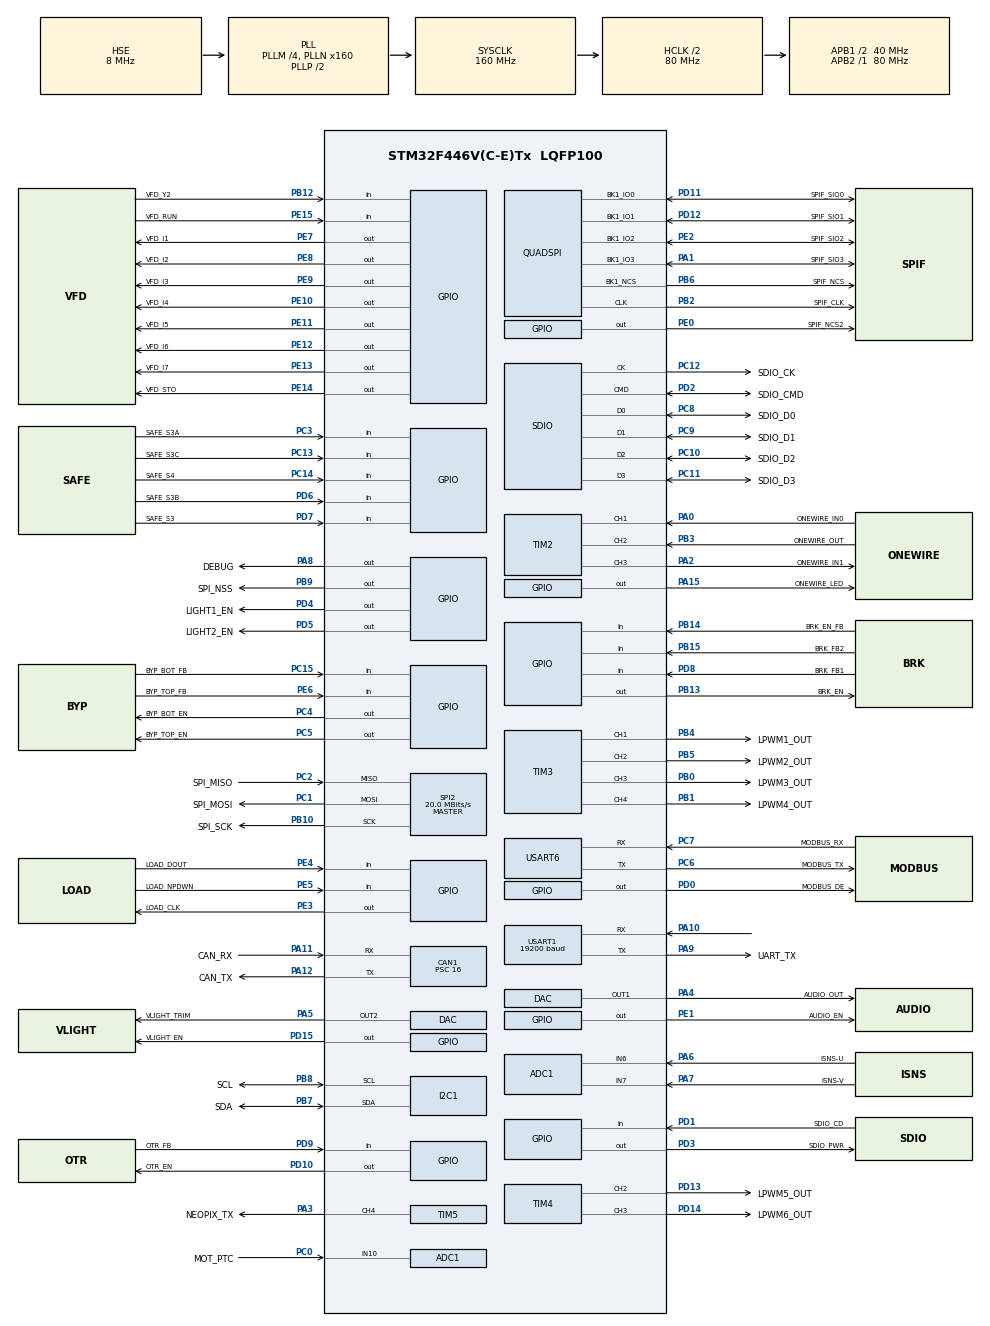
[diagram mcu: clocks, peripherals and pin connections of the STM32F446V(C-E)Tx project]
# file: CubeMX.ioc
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ADC1.Channel-1\#ChannelRegularConversion=ADC_CHANNEL_6
ADC1.NbrOfConversionFlag=1
ADC1.Rank-1\#ChannelRegularConversion=1
ADC1.SamplingTime-1\#ChannelRegularConversion=ADC_SAMPLETIME_3CYCLES
ADC1.master=1
CAN1.ABOM=ENABLE
CAN1.BS1=CAN_BS1_16TQ
CAN1.BS2=CAN_BS2_3TQ
CAN1.CalculateBaudRate=125000
CAN1.CalculateTimeBit=8000
CAN1.CalculateTimeQuantum=400.0
CAN1.NART=ENABLE
CAN1.Prescaler=16
DAC.DAC_Trigger=DAC_TRIGGER_T6_TRGO
DAC.DAC_Trigger2=DAC_TRIGGER_SOFTWARE
Mcu.Family=STM32F4
Mcu.Name=STM32F446V(C-E)Tx
Mcu.Package=LQFP100
NVIC.PriorityGroup=NVIC_PRIORITYGROUP_4
NVIC.USART1_IRQn=true\:0\:0\:false\:false\:true\:true\:true\:true
PA0-WKUP.GPIO_Label=ONEWIRE_IN0
PA0-WKUP.Signal=S_TIM2_CH1_ETR
PA1.GPIO_Label=SPIF_SIO3
PA1.Mode=Single Bank 1
PA1.Signal=QUADSPI_BK1_IO3
PA10.Mode=Asynchronous
PA10.Signal=USART1_RX
PA11.GPIO_Label=CAN_RX
PA11.Mode=CAN_Activate
PA11.Signal=CAN1_RX
PA12.GPIO_Label=CAN_TX
PA12.Mode=CAN_Activate
PA12.Signal=CAN1_TX
PA13.GPIO_Label=SWDIO
PA13.Mode=Serial_Wire
PA13.Signal=SYS_JTMS-SWDIO
PA14.GPIO_Label=SWCLK
PA14.Mode=Serial_Wire
PA14.Signal=SYS_JTCK-SWCLK
PA15.GPIO_Label=ONEWIRE_LED
PA15.Signal=GPIO_Output
PA2.GPIO_Label=ONEWIRE_IN1
PA2.Signal=S_TIM2_CH3
PA3.GPIO_Label=NEOPIX_TX
PA3.Signal=S_TIM5_CH4
PA4.GPIO_Label=AUDIO_OUT
PA4.Signal=COMP_DAC1_group
PA5.GPIO_Label=VLIGHT_TRIM
PA5.Signal=COMP_DAC2_group
PA6.GPIO_Label=ISNS-U
PA6.Signal=ADCx_IN6
PA7.GPIO_Label=ISNS-V
PA7.Signal=ADCx_IN7
PA8.GPIO_Label=DEBUG
PA8.Signal=GPIO_Output
PA9.GPIO_Label=UART_TX
PA9.Mode=Asynchronous
PA9.Signal=USART1_TX
PB0.GPIO_Label=LPWM3_OUT
PB0.Signal=S_TIM3_CH3
PB1.GPIO_Label=LPWM4_OUT
PB1.Signal=S_TIM3_CH4
PB10.GPIO_Label=SPI_SCK
PB10.Mode=Full_Duplex_Master
PB10.Signal=SPI2_SCK
PB12.GPIO_Label=VFD_Y2
PB12.Signal=GPIO_Input
PB13.GPIO_Label=BRK_EN
PB13.Signal=GPIO_Output
PB14.GPIO_Label=BRK_EN_FB
PB14.Signal=GPIO_Input
PB15.GPIO_Label=BRK_FB2
PB15.Signal=GPIO_Input
PB2.GPIO_Label=SPIF_CLK
PB2.Mode=Single Bank 1
PB2.Signal=QUADSPI_CLK
PB3.GPIO_Label=ONEWIRE_OUT
PB3.GPIO_Speed=GPIO_SPEED_FREQ_HIGH
PB3.Signal=S_TIM2_CH2
PB4.GPIO_Label=LPWM1_OUT
PB4.Signal=S_TIM3_CH1
PB5.GPIO_Label=LPWM2_OUT
PB5.Signal=S_TIM3_CH2
PB6.GPIO_Label=SPIF_NCS
PB6.Mode=Single Bank 1
PB6.Signal=QUADSPI_BK1_NCS
PB7.GPIO_Label=SDA
PB7.Mode=I2C
PB7.Signal=I2C1_SDA
PB8.GPIO_Label=SCL
PB8.Mode=I2C
PB8.Signal=I2C1_SCL
PB9.GPIO_Label=SPI_NSS
PB9.Signal=GPIO_Output
PC0.GPIO_Label=MOT_PTC
PC0.Signal=ADCx_IN10
PC1.GPIO_Label=SPI_MOSI
PC1.Mode=Full_Duplex_Master
PC1.Signal=SPI2_MOSI
PC10.GPIO_Label=SDIO_D2
PC10.Mode=SD_4_bits_Wide_bus
PC10.Signal=SDIO_D2
PC11.GPIO_Label=SDIO_D3
PC11.Mode=SD_4_bits_Wide_bus
PC11.Signal=SDIO_D3
PC12.GPIO_Label=SDIO_CK
PC12.Mode=SD_4_bits_Wide_bus
PC12.Signal=SDIO_CK
PC13.GPIO_Label=SAFE_S3C
PC13.Signal=GPIO_Input
PC14-OSC32_IN.GPIO_Label=SAFE_S4
PC14-OSC32_IN.Signal=GPIO_Input
PC15-OSC32_OUT.GPIO_Label=BYP_BOT_FB
PC15-OSC32_OUT.GPIO_PuPd=GPIO_PULLDOWN
PC15-OSC32_OUT.Signal=GPIO_Input
PC2.GPIO_Label=SPI_MISO
PC2.Mode=Full_Duplex_Master
PC2.Signal=SPI2_MISO
PC3.GPIO_Label=SAFE_S3A
PC3.Signal=GPIO_Input
PC4.GPIO_Label=BYP_BOT_EN
PC4.Signal=GPIO_Output
PC5.GPIO_Label=BYP_TOP_EN
PC5.Signal=GPIO_Output
PC6.GPIO_Label=MODBUS_TX
PC6.Mode=Asynchronous
PC6.Signal=USART6_TX
PC7.GPIO_Label=MODBUS_RX
PC7.Mode=Asynchronous
PC7.Signal=USART6_RX
PC8.GPIO_Label=SDIO_D0
PC8.Mode=SD_4_bits_Wide_bus
PC8.Signal=SDIO_D0
PC9.GPIO_Label=SDIO_D1
PC9.Mode=SD_4_bits_Wide_bus
PC9.Signal=SDIO_D1
PD0.GPIO_Label=MODBUS_DE
PD0.Signal=GPIO_Output
PD1.GPIO_Label=SDIO_CD
PD1.Signal=GPIO_Input
PD10.GPIO_Label=OTR_EN
PD10.Signal=GPIO_Output
PD11.GPIO_Label=SPIF_SIO0
PD11.Mode=Single Bank 1
PD11.Signal=QUADSPI_BK1_IO0
PD12.GPIO_Label=SPIF_SIO1
PD12.Mode=Single Bank 1
PD12.Signal=QUADSPI_BK1_IO1
PD13.GPIO_Label=LPWM5_OUT
PD13.Signal=S_TIM4_CH2
PD14.GPIO_Label=LPWM6_OUT
PD14.Signal=S_TIM4_CH3
PD15.GPIO_Label=VLIGHT_EN
PD15.Signal=GPIO_Output
PD2.GPIO_Label=SDIO_CMD
PD2.Mode=SD_4_bits_Wide_bus
PD2.Signal=SDIO_CMD
PD3.GPIO_Label=SDIO_PWR
PD3.Signal=GPIO_Output
PD4.GPIO_Label=LIGHT1_EN
PD4.Signal=GPIO_Output
PD5.GPIO_Label=LIGHT2_EN
PD5.Signal=GPIO_Output
PD6.GPIO_Label=SAFE_S3B
PD6.Signal=GPIO_Input
PD7.GPIO_Label=SAFE_S3
PD7.Signal=GPIO_Input
PD8.GPIO_Label=BRK_FB1
PD8.Signal=GPIO_Input
PD9.GPIO_Label=OTR_FB
PD9.Signal=GPIO_Input
PE0.GPIO_Label=SPIF_NCS2
PE0.Signal=GPIO_Output
PE1.GPIO_Label=AUDIO_EN
PE1.Signal=GPIO_Output
PE10.GPIO_Label=VFD_I4
PE10.Signal=GPIO_Output
PE11.GPIO_Label=VFD_I5
PE11.Signal=GPIO_Output
PE12.GPIO_Label=VFD_I6
PE12.Signal=GPIO_Output
PE13.GPIO_Label=VFD_I7
PE13.Signal=GPIO_Output
PE14.GPIO_Label=VFD_STO
PE14.Signal=GPIO_Output
PE15.GPIO_Label=VFD_RUN
PE15.Signal=GPIO_Input
PE2.GPIO_Label=SPIF_SIO2
PE2.Mode=Single Bank 1
PE2.Signal=QUADSPI_BK1_IO2
PE3.GPIO_Label=LOAD_CLK
PE3.Signal=GPIO_Output
PE4.GPIO_Label=LOAD_DOUT
PE4.Signal=GPIO_Input
PE5.GPIO_Label=LOAD_NPDWN
PE5.Signal=GPIO_Input
PE6.GPIO_Label=BYP_TOP_FB
PE6.GPIO_PuPd=GPIO_PULLDOWN
PE6.Signal=GPIO_Input
PE7.GPIO_Label=VFD_I1
PE7.Signal=GPIO_Output
PE8.GPIO_Label=VFD_I2
PE8.Signal=GPIO_Output
PE9.GPIO_Label=VFD_I3
PE9.Signal=GPIO_Output
PH0-OSC_IN.GPIO_Label=OSCI1
PH0-OSC_IN.Mode=HSE-External-Oscillator
PH0-OSC_IN.Signal=RCC_OSC_IN
PH1-OSC_OUT.GPIO_Label=OSCO1
PH1-OSC_OUT.Mode=HSE-External-Oscillator
PH1-OSC_OUT.Signal=RCC_OSC_OUT
ProjectManager.HeapSize=0x200
ProjectManager.StackSize=0x400
ProjectManager.TargetToolchain=STM32CubeIDE
RCC.AHBCLKDivider=RCC_SYSCLK_DIV2
RCC.AHBFreq_Value=80000000
RCC.APB1CLKDivider=RCC_HCLK_DIV2
RCC.APB1Freq_Value=40000000
RCC.APB1TimFreq_Value=80000000
RCC.APB2Freq_Value=80000000
RCC.APB2TimFreq_Value=80000000
RCC.CortexFreq_Value=80000000
RCC.HCLKFreq_Value=80000000
RCC.HSE_VALUE=8000000
RCC.PLLM=4
RCC.PLLN=160
RCC.PLLQ=8
RCC.PLLSourceVirtual=RCC_PLLSOURCE_HSE
RCC.SYSCLKFreq_VALUE=160000000
RCC.SYSCLKSource=RCC_SYSCLKSOURCE_PLLCLK
RCC.USBFreq_Value=40000000
RCC.VCOOutputFreq_Value=320000000
SH.ADCx_IN10.0=ADC1_IN10,IN10
SH.ADCx_IN6.0=ADC1_IN6,IN6
SH.ADCx_IN7.0=ADC1_IN7,IN7
SH.COMP_DAC1_group.0=DAC_OUT1,DAC_OUT1
SH.COMP_DAC2_group.0=DAC_OUT2,DAC_OUT2
SH.S_TIM2_CH1_ETR.0=TIM2_CH1,Input_Capture1_from_TI1
SH.S_TIM2_CH2.0=TIM2_CH2,Input_Capture2_from_TI2
SH.S_TIM2_CH3.0=TIM2_CH3,Output Compare3 CH3
SH.S_TIM3_CH1.0=TIM3_CH1,PWM Generation1 CH1
SH.S_TIM3_CH2.0=TIM3_CH2,PWM Generation2 CH2
SH.S_TIM3_CH3.0=TIM3_CH3,PWM Generation3 CH3
SH.S_TIM3_CH4.0=TIM3_CH4,PWM Generation4 CH4
SH.S_TIM4_CH2.0=TIM4_CH2,PWM Generation2 CH2
SH.S_TIM4_CH3.0=TIM4_CH3,PWM Generation3 CH3
SH.S_TIM5_CH4.0=TIM5_CH4,Output Compare4 CH4
SPI2.BaudRatePrescaler=SPI_BAUDRATEPRESCALER_2
SPI2.CalculateBaudRate=20.0 MBits/s
SPI2.Direction=SPI_DIRECTION_2LINES
SPI2.Mode=SPI_MODE_MASTER
SPI2.VirtualType=VM_MASTER
TIM2.Channel-Input_Capture1_from_TI1=TIM_CHANNEL_1
TIM2.Channel-Input_Capture2_from_TI2=TIM_CHANNEL_2
TIM2.Channel-Output\ Compare3\ CH3=TIM_CHANNEL_3
TIM2.ICPolarity_CH2=TIM_INPUTCHANNELPOLARITY_FALLING
TIM2.OCMode_3=TIM_OCMODE_ACTIVE
TIM3.Channel-PWM\ Generation1\ CH1=TIM_CHANNEL_1
TIM3.Channel-PWM\ Generation2\ CH2=TIM_CHANNEL_2
TIM3.Channel-PWM\ Generation3\ CH3=TIM_CHANNEL_3
TIM3.Channel-PWM\ Generation4\ CH4=TIM_CHANNEL_4
TIM4.Channel-PWM\ Generation2\ CH2=TIM_CHANNEL_2
TIM4.Channel-PWM\ Generation3\ CH3=TIM_CHANNEL_3
TIM5.Channel-Output\ Compare4\ CH4=TIM_CHANNEL_4
TIM6.TIM_MasterOutputTrigger=TIM_TRGO_RESET
USART1.BaudRate=19200
USART1.VirtualMode=VM_ASYNC
USART1.WordLength=WORDLENGTH_8B
USART6.VirtualMode=VM_ASYNC
VP_IWDG_VS_IWDG.Mode=IWDG_Activate
VP_TIM2_VS_ClockSourceINT.Mode=Internal
VP_TIM3_VS_ClockSourceINT.Mode=Internal
VP_TIM4_VS_ClockSourceINT.Mode=Internal
VP_TIM5_VS_ClockSourceINT.Mode=Internal
VP_TIM6_VS_ClockSourceINT.Mode=Enable_Timer
board=custom

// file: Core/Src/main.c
/* USER CODE BEGIN Header */
/**
  ******************************************************************************
  * @file           : main.c
  * @brief          : Main program body
  ******************************************************************************
  * @attention
  *
  * Copyright (c) 2026 STMicroelectronics.
  * All rights reserved.
  *
  * This software is licensed under terms that can be found in the LICENSE file
  * in the root directory of this software component.
  * If no LICENSE file comes with this software, it is provided AS-IS.
  *
  ******************************************************************************
  */
/* USER CODE END Header */
#include "main.h"

ADC_HandleTypeDef hadc1;

CAN_HandleTypeDef hcan1;

DAC_HandleTypeDef hdac;

I2C_HandleTypeDef hi2c1;

IWDG_HandleTypeDef hiwdg;

QSPI_HandleTypeDef hqspi;

SD_HandleTypeDef hsd;

SPI_HandleTypeDef hspi2;

TIM_HandleTypeDef htim2;
TIM_HandleTypeDef htim3;
TIM_HandleTypeDef htim4;
TIM_HandleTypeDef htim5;
TIM_HandleTypeDef htim6;

UART_HandleTypeDef huart1;
UART_HandleTypeDef huart6;

void SystemClock_Config(void);
static void MX_GPIO_Init(void);
static void MX_CAN1_Init(void);
static void MX_DAC_Init(void);
static void MX_QUADSPI_Init(void);
static void MX_SDIO_SD_Init(void);
static void MX_TIM3_Init(void);
static void MX_TIM4_Init(void);
static void MX_TIM6_Init(void);
static void MX_IWDG_Init(void);
static void MX_ADC1_Init(void);
static void MX_I2C1_Init(void);
static void MX_SPI2_Init(void);
static void MX_TIM2_Init(void);
static void MX_USART1_UART_Init(void);
static void MX_USART6_UART_Init(void);
static void MX_TIM5_Init(void);

int main(void)
{

  /* MCU Configuration--------------------------------------------------------*/

  /* Reset of all peripherals, Initializes the Flash interface and the Systick. */
  HAL_Init();

  /* Configure the system clock */
  SystemClock_Config();

  /* Initialize all configured peripherals */
  MX_GPIO_Init();
  MX_CAN1_Init();
  MX_DAC_Init();
  MX_QUADSPI_Init();
  MX_SDIO_SD_Init();
  MX_TIM3_Init();
  MX_TIM4_Init();
  MX_TIM6_Init();
  MX_IWDG_Init();
  MX_ADC1_Init();
  MX_I2C1_Init();
  MX_SPI2_Init();
  MX_TIM2_Init();
  MX_USART1_UART_Init();
  MX_USART6_UART_Init();
  MX_TIM5_Init();
  /* USER CODE BEGIN 2 */

  HAL_ADC_Start(&hadc1);
  HAL_TIM_Base_Start(&htim2);
  HAL_TIM_Base_Start(&htim4);
  HAL_TIM_Base_Start(&htim5);
  HAL_TIM_Base_Start(&htim6);

  HAL_TIM_PWM_Start(&htim4, TIM_CHANNEL_3);

  /* bank 0 e bank 1 libere */
  CAN_FilterTypeDef filt_cfg = {
      .FilterBank = 0,
      .FilterIdHigh = 0x0000,
      .FilterIdLow = 0x0000,
      .FilterMaskIdHigh = 0x0000,
      .FilterMaskIdLow = 0x0000,
      .FilterFIFOAssignment = CAN_FILTER_FIFO0,
      .FilterMode = CAN_FILTERMODE_IDMASK,
      .FilterScale = CAN_FILTERSCALE_32BIT,
      .FilterActivation = CAN_FILTER_ENABLE,
      .SlaveStartFilterBank = 13,
  };
  HAL_CAN_ConfigFilter(&hcan1, &filt_cfg);
  filt_cfg.FilterBank = 1,
  filt_cfg.FilterFIFOAssignment = CAN_FILTER_FIFO1;
  HAL_CAN_ConfigFilter(&hcan1, &filt_cfg);

  /* configurazione timer */
  tmr_config(TMR_ID_UDEC_CX_UPDATE, TMR_TYPE_IEC_TON, 1000);
  tmr_config(TMR_ID_ELT_PWM, TMR_TYPE_IEC_TON, 100);
  tmr_config(TMR_ID_DEBUG_LED, TMR_TYPE_IEC_TON, 250);
  tmr_config(TMR_ID_NMT_DELAY, TMR_TYPE_IEC_TON, 100);
  tmr_config(TMR_ID_NMT_TIMEOUT, TMR_TYPE_IEC_TON, 200);
  /**/

  HAL_CAN_Start(&hcan1);

  /* USER CODE END 2 */

  /* Infinite loop */
  while (1)
  {

    /* USER CODE BEGIN 3 */
	  HAL_IWDG_Refresh(&hiwdg);
	  main_loop();
  }
  /* USER CODE END 3 */
}

void SystemClock_Config(void)
{
  RCC_OscInitTypeDef RCC_OscInitStruct = {0};
  RCC_ClkInitTypeDef RCC_ClkInitStruct = {0};

  /** Configure the main internal regulator output voltage
  */
  __HAL_RCC_PWR_CLK_ENABLE();
  __HAL_PWR_VOLTAGESCALING_CONFIG(PWR_REGULATOR_VOLTAGE_SCALE3);

  /** Initializes the RCC Oscillators according to the specified parameters
  * in the RCC_OscInitTypeDef structure.
  */
  RCC_OscInitStruct.OscillatorType = RCC_OSCILLATORTYPE_LSI|RCC_OSCILLATORTYPE_HSE;
  RCC_OscInitStruct.HSEState = RCC_HSE_ON;
  RCC_OscInitStruct.LSIState = RCC_LSI_ON;
  RCC_OscInitStruct.PLL.PLLState = RCC_PLL_ON;
  RCC_OscInitStruct.PLL.PLLSource = RCC_PLLSOURCE_HSE;
  RCC_OscInitStruct.PLL.PLLM = 4;
  RCC_OscInitStruct.PLL.PLLN = 160;
  RCC_OscInitStruct.PLL.PLLP = RCC_PLLP_DIV2;
  RCC_OscInitStruct.PLL.PLLQ = 8;
  RCC_OscInitStruct.PLL.PLLR = 2;
  if (HAL_RCC_OscConfig(&RCC_OscInitStruct) != HAL_OK)
  {
    Error_Handler();
  }

  /** Initializes the CPU, AHB and APB buses clocks
  */
  RCC_ClkInitStruct.ClockType = RCC_CLOCKTYPE_HCLK|RCC_CLOCKTYPE_SYSCLK
                              |RCC_CLOCKTYPE_PCLK1|RCC_CLOCKTYPE_PCLK2;
  RCC_ClkInitStruct.SYSCLKSource = RCC_SYSCLKSOURCE_PLLCLK;
  RCC_ClkInitStruct.AHBCLKDivider = RCC_SYSCLK_DIV2;
  RCC_ClkInitStruct.APB1CLKDivider = RCC_HCLK_DIV2;
  RCC_ClkInitStruct.APB2CLKDivider = RCC_HCLK_DIV1;

  if (HAL_RCC_ClockConfig(&RCC_ClkInitStruct, FLASH_LATENCY_2) != HAL_OK)
  {
    Error_Handler();
  }
}

static void MX_ADC1_Init(void)
{

  ADC_ChannelConfTypeDef sConfig = {0};

  /** Configure the global features of the ADC (Clock, Resolution, Data Alignment and number of conversion)
  */
  hadc1.Instance = ADC1;
  hadc1.Init.ClockPrescaler = ADC_CLOCK_SYNC_PCLK_DIV4;
  hadc1.Init.Resolution = ADC_RESOLUTION_12B;
  hadc1.Init.ScanConvMode = DISABLE;
  hadc1.Init.ContinuousConvMode = DISABLE;
  hadc1.Init.DiscontinuousConvMode = DISABLE;
  hadc1.Init.ExternalTrigConvEdge = ADC_EXTERNALTRIGCONVEDGE_NONE;
  hadc1.Init.ExternalTrigConv = ADC_SOFTWARE_START;
  hadc1.Init.DataAlign = ADC_DATAALIGN_RIGHT;
  hadc1.Init.NbrOfConversion = 1;
  hadc1.Init.DMAContinuousRequests = DISABLE;
  hadc1.Init.EOCSelection = ADC_EOC_SINGLE_CONV;
  if (HAL_ADC_Init(&hadc1) != HAL_OK)
  {
    Error_Handler();
  }

  /** Configure for the selected ADC regular channel its corresponding rank in the sequencer and its sample time.
  */
  sConfig.Channel = ADC_CHANNEL_6;
  sConfig.Rank = 1;
  sConfig.SamplingTime = ADC_SAMPLETIME_3CYCLES;
  if (HAL_ADC_ConfigChannel(&hadc1, &sConfig) != HAL_OK)
  {
    Error_Handler();
  }

}

static void MX_CAN1_Init(void)
{

  hcan1.Instance = CAN1;
  hcan1.Init.Prescaler = 16;
  hcan1.Init.Mode = CAN_MODE_NORMAL;
  hcan1.Init.SyncJumpWidth = CAN_SJW_1TQ;
  hcan1.Init.TimeSeg1 = CAN_BS1_16TQ;
  hcan1.Init.TimeSeg2 = CAN_BS2_3TQ;
  hcan1.Init.TimeTriggeredMode = DISABLE;
  hcan1.Init.AutoBusOff = ENABLE;
  hcan1.Init.AutoWakeUp = DISABLE;
  hcan1.Init.AutoRetransmission = ENABLE;
  hcan1.Init.ReceiveFifoLocked = DISABLE;
  hcan1.Init.TransmitFifoPriority = DISABLE;
  if (HAL_CAN_Init(&hcan1) != HAL_OK)
  {
    Error_Handler();
  }

}

static void MX_DAC_Init(void)
{

  DAC_ChannelConfTypeDef sConfig = {0};

  /** DAC Initialization
  */
  hdac.Instance = DAC;
  if (HAL_DAC_Init(&hdac) != HAL_OK)
  {
    Error_Handler();
  }

  /** DAC channel OUT1 config
  */
  sConfig.DAC_Trigger = DAC_TRIGGER_T6_TRGO;
  sConfig.DAC_OutputBuffer = DAC_OUTPUTBUFFER_ENABLE;
  if (HAL_DAC_ConfigChannel(&hdac, &sConfig, DAC_CHANNEL_1) != HAL_OK)
  {
    Error_Handler();
  }

  /** DAC channel OUT2 config
  */
  sConfig.DAC_Trigger = DAC_TRIGGER_SOFTWARE;
  if (HAL_DAC_ConfigChannel(&hdac, &sConfig, DAC_CHANNEL_2) != HAL_OK)
  {
    Error_Handler();
  }

}

static void MX_I2C1_Init(void)
{

  hi2c1.Instance = I2C1;
  hi2c1.Init.ClockSpeed = 100000;
  hi2c1.Init.DutyCycle = I2C_DUTYCYCLE_2;
  hi2c1.Init.OwnAddress1 = 0;
  hi2c1.Init.AddressingMode = I2C_ADDRESSINGMODE_7BIT;
  hi2c1.Init.DualAddressMode = I2C_DUALADDRESS_DISABLE;
  hi2c1.Init.OwnAddress2 = 0;
  hi2c1.Init.GeneralCallMode = I2C_GENERALCALL_DISABLE;
  hi2c1.Init.NoStretchMode = I2C_NOSTRETCH_DISABLE;
  if (HAL_I2C_Init(&hi2c1) != HAL_OK)
  {
    Error_Handler();
  }

}

static void MX_IWDG_Init(void)
{

  hiwdg.Instance = IWDG;
  hiwdg.Init.Prescaler = IWDG_PRESCALER_4;
  hiwdg.Init.Reload = 4095;
  if (HAL_IWDG_Init(&hiwdg) != HAL_OK)
  {
    Error_Handler();
  }

}

static void MX_QUADSPI_Init(void)
{

  /* QUADSPI parameter configuration*/
  hqspi.Instance = QUADSPI;
  hqspi.Init.ClockPrescaler = 255;
  hqspi.Init.FifoThreshold = 1;
  hqspi.Init.SampleShifting = QSPI_SAMPLE_SHIFTING_NONE;
  hqspi.Init.FlashSize = 1;
  hqspi.Init.ChipSelectHighTime = QSPI_CS_HIGH_TIME_1_CYCLE;
  hqspi.Init.ClockMode = QSPI_CLOCK_MODE_0;
  hqspi.Init.FlashID = QSPI_FLASH_ID_1;
  hqspi.Init.DualFlash = QSPI_DUALFLASH_DISABLE;
  if (HAL_QSPI_Init(&hqspi) != HAL_OK)
  {
    Error_Handler();
  }

}

static void MX_SDIO_SD_Init(void)
{

  hsd.Instance = SDIO;
  hsd.Init.ClockEdge = SDIO_CLOCK_EDGE_RISING;
  hsd.Init.ClockBypass = SDIO_CLOCK_BYPASS_DISABLE;
  hsd.Init.ClockPowerSave = SDIO_CLOCK_POWER_SAVE_DISABLE;
  hsd.Init.BusWide = SDIO_BUS_WIDE_1B;
  hsd.Init.HardwareFlowControl = SDIO_HARDWARE_FLOW_CONTROL_DISABLE;
  hsd.Init.ClockDiv = 0;
  if (HAL_SD_Init(&hsd) != HAL_OK)
  {
    Error_Handler();
  }
  if (HAL_SD_ConfigWideBusOperation(&hsd, SDIO_BUS_WIDE_4B) != HAL_OK)
  {
    Error_Handler();
  }

}

static void MX_SPI2_Init(void)
{

  /* SPI2 parameter configuration*/
  hspi2.Instance = SPI2;
  hspi2.Init.Mode = SPI_MODE_MASTER;
  hspi2.Init.Direction = SPI_DIRECTION_2LINES;
  hspi2.Init.DataSize = SPI_DATASIZE_8BIT;
  hspi2.Init.CLKPolarity = SPI_POLARITY_LOW;
  hspi2.Init.CLKPhase = SPI_PHASE_1EDGE;
  hspi2.Init.NSS = SPI_NSS_SOFT;
  hspi2.Init.BaudRatePrescaler = SPI_BAUDRATEPRESCALER_2;
  hspi2.Init.FirstBit = SPI_FIRSTBIT_MSB;
  hspi2.Init.TIMode = SPI_TIMODE_DISABLE;
  hspi2.Init.CRCCalculation = SPI_CRCCALCULATION_DISABLE;
  hspi2.Init.CRCPolynomial = 10;
  if (HAL_SPI_Init(&hspi2) != HAL_OK)
  {
    Error_Handler();
  }

}

static void MX_TIM2_Init(void)
{

  TIM_ClockConfigTypeDef sClockSourceConfig = {0};
  TIM_MasterConfigTypeDef sMasterConfig = {0};
  TIM_IC_InitTypeDef sConfigIC = {0};
  TIM_OC_InitTypeDef sConfigOC = {0};

  htim2.Instance = TIM2;
  htim2.Init.Prescaler = 0;
  htim2.Init.CounterMode = TIM_COUNTERMODE_UP;
  htim2.Init.Period = 4294967295;
  htim2.Init.ClockDivision = TIM_CLOCKDIVISION_DIV1;
  htim2.Init.AutoReloadPreload = TIM_AUTORELOAD_PRELOAD_DISABLE;
  if (HAL_TIM_Base_Init(&htim2) != HAL_OK)
  {
    Error_Handler();
  }
  sClockSourceConfig.ClockSource = TIM_CLOCKSOURCE_INTERNAL;
  if (HAL_TIM_ConfigClockSource(&htim2, &sClockSourceConfig) != HAL_OK)
  {
    Error_Handler();
  }
  if (HAL_TIM_IC_Init(&htim2) != HAL_OK)
  {
    Error_Handler();
  }
  if (HAL_TIM_OC_Init(&htim2) != HAL_OK)
  {
    Error_Handler();
  }
  sMasterConfig.MasterOutputTrigger = TIM_TRGO_RESET;
  sMasterConfig.MasterSlaveMode = TIM_MASTERSLAVEMODE_DISABLE;
  if (HAL_TIMEx_MasterConfigSynchronization(&htim2, &sMasterConfig) != HAL_OK)
  {
    Error_Handler();
  }
  sConfigIC.ICPolarity = TIM_INPUTCHANNELPOLARITY_RISING;
  sConfigIC.ICSelection = TIM_ICSELECTION_DIRECTTI;
  sConfigIC.ICPrescaler = TIM_ICPSC_DIV1;
  sConfigIC.ICFilter = 0;
  if (HAL_TIM_IC_ConfigChannel(&htim2, &sConfigIC, TIM_CHANNEL_1) != HAL_OK)
  {
    Error_Handler();
  }
  sConfigIC.ICPolarity = TIM_INPUTCHANNELPOLARITY_FALLING;
  if (HAL_TIM_IC_ConfigChannel(&htim2, &sConfigIC, TIM_CHANNEL_2) != HAL_OK)
  {
    Error_Handler();
  }
  sConfigOC.OCMode = TIM_OCMODE_ACTIVE;
  sConfigOC.Pulse = 0;
  sConfigOC.OCPolarity = TIM_OCPOLARITY_HIGH;
  sConfigOC.OCFastMode = TIM_OCFAST_DISABLE;
  if (HAL_TIM_OC_ConfigChannel(&htim2, &sConfigOC, TIM_CHANNEL_3) != HAL_OK)
  {
    Error_Handler();
  }
  HAL_TIM_MspPostInit(&htim2);

}

static void MX_TIM3_Init(void)
{

  TIM_ClockConfigTypeDef sClockSourceConfig = {0};
  TIM_MasterConfigTypeDef sMasterConfig = {0};
  TIM_OC_InitTypeDef sConfigOC = {0};

  htim3.Instance = TIM3;
  htim3.Init.Prescaler = 0;
  htim3.Init.CounterMode = TIM_COUNTERMODE_UP;
  htim3.Init.Period = 65535;
  htim3.Init.ClockDivision = TIM_CLOCKDIVISION_DIV1;
  htim3.Init.AutoReloadPreload = TIM_AUTORELOAD_PRELOAD_DISABLE;
  if (HAL_TIM_Base_Init(&htim3) != HAL_OK)
  {
    Error_Handler();
  }
  sClockSourceConfig.ClockSource = TIM_CLOCKSOURCE_INTERNAL;
  if (HAL_TIM_ConfigClockSource(&htim3, &sClockSourceConfig) != HAL_OK)
  {
    Error_Handler();
  }
  if (HAL_TIM_PWM_Init(&htim3) != HAL_OK)
  {
    Error_Handler();
  }
  sMasterConfig.MasterOutputTrigger = TIM_TRGO_RESET;
  sMasterConfig.MasterSlaveMode = TIM_MASTERSLAVEMODE_DISABLE;
  if (HAL_TIMEx_MasterConfigSynchronization(&htim3, &sMasterConfig) != HAL_OK)
  {
    Error_Handler();
  }
  sConfigOC.OCMode = TIM_OCMODE_PWM1;
  sConfigOC.Pulse = 0;
  sConfigOC.OCPolarity = TIM_OCPOLARITY_HIGH;
  sConfigOC.OCFastMode = TIM_OCFAST_DISABLE;
  if (HAL_TIM_PWM_ConfigChannel(&htim3, &sConfigOC, TIM_CHANNEL_1) != HAL_OK)
  {
    Error_Handler();
  }
  if (HAL_TIM_PWM_ConfigChannel(&htim3, &sConfigOC, TIM_CHANNEL_2) != HAL_OK)
  {
    Error_Handler();
  }
  if (HAL_TIM_PWM_ConfigChannel(&htim3, &sConfigOC, TIM_CHANNEL_3) != HAL_OK)
  {
    Error_Handler();
  }
  if (HAL_TIM_PWM_ConfigChannel(&htim3, &sConfigOC, TIM_CHANNEL_4) != HAL_OK)
  {
    Error_Handler();
  }
  HAL_TIM_MspPostInit(&htim3);

}

static void MX_TIM4_Init(void)
{

  TIM_ClockConfigTypeDef sClockSourceConfig = {0};
  TIM_MasterConfigTypeDef sMasterConfig = {0};
  TIM_OC_InitTypeDef sConfigOC = {0};

  htim4.Instance = TIM4;
  htim4.Init.Prescaler = 0;
  htim4.Init.CounterMode = TIM_COUNTERMODE_UP;
  htim4.Init.Period = 65535;
  htim4.Init.ClockDivision = TIM_CLOCKDIVISION_DIV1;
  htim4.Init.AutoReloadPreload = TIM_AUTORELOAD_PRELOAD_DISABLE;
  if (HAL_TIM_Base_Init(&htim4) != HAL_OK)
  {
    Error_Handler();
  }
  sClockSourceConfig.ClockSource = TIM_CLOCKSOURCE_INTERNAL;
  if (HAL_TIM_ConfigClockSource(&htim4, &sClockSourceConfig) != HAL_OK)
  {
    Error_Handler();
  }
  if (HAL_TIM_PWM_Init(&htim4) != HAL_OK)
  {
    Error_Handler();
  }
  sMasterConfig.MasterOutputTrigger = TIM_TRGO_RESET;
  sMasterConfig.MasterSlaveMode = TIM_MASTERSLAVEMODE_DISABLE;
  if (HAL_TIMEx_MasterConfigSynchronization(&htim4, &sMasterConfig) != HAL_OK)
  {
    Error_Handler();
  }
  sConfigOC.OCMode = TIM_OCMODE_PWM1;
  sConfigOC.Pulse = 0;
  sConfigOC.OCPolarity = TIM_OCPOLARITY_HIGH;
  sConfigOC.OCFastMode = TIM_OCFAST_DISABLE;
  if (HAL_TIM_PWM_ConfigChannel(&htim4, &sConfigOC, TIM_CHANNEL_2) != HAL_OK)
  {
    Error_Handler();
  }
  if (HAL_TIM_PWM_ConfigChannel(&htim4, &sConfigOC, TIM_CHANNEL_3) != HAL_OK)
  {
    Error_Handler();
  }
  HAL_TIM_MspPostInit(&htim4);

}

static void MX_TIM5_Init(void)
{

  TIM_ClockConfigTypeDef sClockSourceConfig = {0};
  TIM_MasterConfigTypeDef sMasterConfig = {0};
  TIM_OC_InitTypeDef sConfigOC = {0};

  htim5.Instance = TIM5;
  htim5.Init.Prescaler = 0;
  htim5.Init.CounterMode = TIM_COUNTERMODE_UP;
  htim5.Init.Period = 4294967295;
  htim5.Init.ClockDivision = TIM_CLOCKDIVISION_DIV1;
  htim5.Init.AutoReloadPreload = TIM_AUTORELOAD_PRELOAD_DISABLE;
  if (HAL_TIM_Base_Init(&htim5) != HAL_OK)
  {
    Error_Handler();
  }
  sClockSourceConfig.ClockSource = TIM_CLOCKSOURCE_INTERNAL;
  if (HAL_TIM_ConfigClockSource(&htim5, &sClockSourceConfig) != HAL_OK)
  {
    Error_Handler();
  }
  if (HAL_TIM_OC_Init(&htim5) != HAL_OK)
  {
    Error_Handler();
  }
  sMasterConfig.MasterOutputTrigger = TIM_TRGO_RESET;
  sMasterConfig.MasterSlaveMode = TIM_MASTERSLAVEMODE_DISABLE;
  if (HAL_TIMEx_MasterConfigSynchronization(&htim5, &sMasterConfig) != HAL_OK)
  {
    Error_Handler();
  }
  sConfigOC.OCMode = TIM_OCMODE_TIMING;
  sConfigOC.Pulse = 0;
  sConfigOC.OCPolarity = TIM_OCPOLARITY_HIGH;
  sConfigOC.OCFastMode = TIM_OCFAST_DISABLE;
  if (HAL_TIM_OC_ConfigChannel(&htim5, &sConfigOC, TIM_CHANNEL_4) != HAL_OK)
  {
    Error_Handler();
  }
  HAL_TIM_MspPostInit(&htim5);

}

static void MX_TIM6_Init(void)
{

  TIM_MasterConfigTypeDef sMasterConfig = {0};

  htim6.Instance = TIM6;
  htim6.Init.Prescaler = 0;
  htim6.Init.CounterMode = TIM_COUNTERMODE_UP;
  htim6.Init.Period = 65535;
  htim6.Init.AutoReloadPreload = TIM_AUTORELOAD_PRELOAD_DISABLE;
  if (HAL_TIM_Base_Init(&htim6) != HAL_OK)
  {
    Error_Handler();
  }
  sMasterConfig.MasterOutputTrigger = TIM_TRGO_RESET;
  sMasterConfig.MasterSlaveMode = TIM_MASTERSLAVEMODE_DISABLE;
  if (HAL_TIMEx_MasterConfigSynchronization(&htim6, &sMasterConfig) != HAL_OK)
  {
    Error_Handler();
  }

}

static void MX_USART1_UART_Init(void)
{

  huart1.Instance = USART1;
  huart1.Init.BaudRate = 19200;
  huart1.Init.WordLength = UART_WORDLENGTH_8B;
  huart1.Init.StopBits = UART_STOPBITS_1;
  huart1.Init.Parity = UART_PARITY_NONE;
  huart1.Init.Mode = UART_MODE_TX_RX;
  huart1.Init.HwFlowCtl = UART_HWCONTROL_NONE;
  huart1.Init.OverSampling = UART_OVERSAMPLING_16;
  if (HAL_UART_Init(&huart1) != HAL_OK)
  {
    Error_Handler();
  }

}

static void MX_USART6_UART_Init(void)
{

  huart6.Instance = USART6;
  huart6.Init.BaudRate = 115200;
  huart6.Init.WordLength = UART_WORDLENGTH_8B;
  huart6.Init.StopBits = UART_STOPBITS_1;
  huart6.Init.Parity = UART_PARITY_NONE;
  huart6.Init.Mode = UART_MODE_TX_RX;
  huart6.Init.HwFlowCtl = UART_HWCONTROL_NONE;
  huart6.Init.OverSampling = UART_OVERSAMPLING_16;
  if (HAL_UART_Init(&huart6) != HAL_OK)
  {
    Error_Handler();
  }

}

static void MX_GPIO_Init(void)
{
  GPIO_InitTypeDef GPIO_InitStruct = {0};

  /* GPIO Ports Clock Enable */
  __HAL_RCC_GPIOE_CLK_ENABLE();
  __HAL_RCC_GPIOC_CLK_ENABLE();
  __HAL_RCC_GPIOH_CLK_ENABLE();
  __HAL_RCC_GPIOA_CLK_ENABLE();
  __HAL_RCC_GPIOB_CLK_ENABLE();
  __HAL_RCC_GPIOD_CLK_ENABLE();

  /*Configure GPIO pin Output Level */
  HAL_GPIO_WritePin(GPIOE, LOAD_CLK_Pin|VFD_I1_Pin|VFD_I2_Pin|VFD_I3_Pin
                          |VFD_I4_Pin|VFD_I5_Pin|VFD_I6_Pin|VFD_I7_Pin
                          |VFD_STO_Pin|SPIF_NCS2_Pin|AUDIO_EN_Pin, GPIO_PIN_RESET);

  /*Configure GPIO pin Output Level */
  HAL_GPIO_WritePin(GPIOC, BYP_BOT_EN_Pin|BYP_TOP_EN_Pin, GPIO_PIN_RESET);

  /*Configure GPIO pin Output Level */
  HAL_GPIO_WritePin(GPIOB, BRK_EN_Pin|SPI_NSS_Pin, GPIO_PIN_RESET);

  /*Configure GPIO pin Output Level */
  HAL_GPIO_WritePin(GPIOD, OTR_EN_Pin|VLIGHT_EN_Pin|MODBUS_DE_Pin|SDIO_PWR_Pin
                          |LIGHT1_EN_Pin|LIGHT2_EN_Pin, GPIO_PIN_RESET);

  /*Configure GPIO pin Output Level */
  HAL_GPIO_WritePin(GPIOA, DEBUG_Pin|ONEWIRE_LED_Pin, GPIO_PIN_RESET);

  /*Configure GPIO pins : LOAD_CLK_Pin VFD_I1_Pin VFD_I2_Pin VFD_I3_Pin
                           VFD_I4_Pin VFD_I5_Pin VFD_I6_Pin VFD_I7_Pin
                           VFD_STO_Pin SPIF_NCS2_Pin AUDIO_EN_Pin */
  GPIO_InitStruct.Pin = LOAD_CLK_Pin|VFD_I1_Pin|VFD_I2_Pin|VFD_I3_Pin
                          |VFD_I4_Pin|VFD_I5_Pin|VFD_I6_Pin|VFD_I7_Pin
                          |VFD_STO_Pin|SPIF_NCS2_Pin|AUDIO_EN_Pin;
  GPIO_InitStruct.Mode = GPIO_MODE_OUTPUT_PP;
  GPIO_InitStruct.Pull = GPIO_NOPULL;
  GPIO_InitStruct.Speed = GPIO_SPEED_FREQ_LOW;
  HAL_GPIO_Init(GPIOE, &GPIO_InitStruct);

  /*Configure GPIO pins : LOAD_DOUT_Pin LOAD_NPDWN_Pin VFD_RUN_Pin */
  GPIO_InitStruct.Pin = LOAD_DOUT_Pin|LOAD_NPDWN_Pin|VFD_RUN_Pin;
  GPIO_InitStruct.Mode = GPIO_MODE_INPUT;
  GPIO_InitStruct.Pull = GPIO_NOPULL;
  HAL_GPIO_Init(GPIOE, &GPIO_InitStruct);

  /*Configure GPIO pin : BYP_TOP_FB_Pin */
  GPIO_InitStruct.Pin = BYP_TOP_FB_Pin;
  GPIO_InitStruct.Mode = GPIO_MODE_INPUT;
  GPIO_InitStruct.Pull = GPIO_PULLDOWN;
  HAL_GPIO_Init(BYP_TOP_FB_GPIO_Port, &GPIO_InitStruct);

  /*Configure GPIO pins : SAFE_S3C_Pin SAFE_S4_Pin SAFE_S3A_Pin */
  GPIO_InitStruct.Pin = SAFE_S3C_Pin|SAFE_S4_Pin|SAFE_S3A_Pin;
  GPIO_InitStruct.Mode = GPIO_MODE_INPUT;
  GPIO_InitStruct.Pull = GPIO_NOPULL;
  HAL_GPIO_Init(GPIOC, &GPIO_InitStruct);

  /*Configure GPIO pin : BYP_BOT_FB_Pin */
  GPIO_InitStruct.Pin = BYP_BOT_FB_Pin;
  GPIO_InitStruct.Mode = GPIO_MODE_INPUT;
  GPIO_InitStruct.Pull = GPIO_PULLDOWN;
  HAL_GPIO_Init(BYP_BOT_FB_GPIO_Port, &GPIO_InitStruct);

  /*Configure GPIO pins : BYP_BOT_EN_Pin BYP_TOP_EN_Pin */
  GPIO_InitStruct.Pin = BYP_BOT_EN_Pin|BYP_TOP_EN_Pin;
  GPIO_InitStruct.Mode = GPIO_MODE_OUTPUT_PP;
  GPIO_InitStruct.Pull = GPIO_NOPULL;
  GPIO_InitStruct.Speed = GPIO_SPEED_FREQ_LOW;
  HAL_GPIO_Init(GPIOC, &GPIO_InitStruct);

  /*Configure GPIO pins : VFD_Y2_Pin BRK_EN_FB_Pin BRK_FB2_Pin */
  GPIO_InitStruct.Pin = VFD_Y2_Pin|BRK_EN_FB_Pin|BRK_FB2_Pin;
  GPIO_InitStruct.Mode = GPIO_MODE_INPUT;
  GPIO_InitStruct.Pull = GPIO_NOPULL;
  HAL_GPIO_Init(GPIOB, &GPIO_InitStruct);

  /*Configure GPIO pins : BRK_EN_Pin SPI_NSS_Pin */
  GPIO_InitStruct.Pin = BRK_EN_Pin|SPI_NSS_Pin;
  GPIO_InitStruct.Mode = GPIO_MODE_OUTPUT_PP;
  GPIO_InitStruct.Pull = GPIO_NOPULL;
  GPIO_InitStruct.Speed = GPIO_SPEED_FREQ_LOW;
  HAL_GPIO_Init(GPIOB, &GPIO_InitStruct);

  /*Configure GPIO pins : BRK_FB1_Pin OTR_FB_Pin SDIO_CD_Pin SAFE_S3B_Pin
                           SAFE_S3_Pin */
  GPIO_InitStruct.Pin = BRK_FB1_Pin|OTR_FB_Pin|SDIO_CD_Pin|SAFE_S3B_Pin
                          |SAFE_S3_Pin;
  GPIO_InitStruct.Mode = GPIO_MODE_INPUT;
  GPIO_InitStruct.Pull = GPIO_NOPULL;
  HAL_GPIO_Init(GPIOD, &GPIO_InitStruct);

  /*Configure GPIO pins : OTR_EN_Pin VLIGHT_EN_Pin MODBUS_DE_Pin SDIO_PWR_Pin
                           LIGHT1_EN_Pin LIGHT2_EN_Pin */
  GPIO_InitStruct.Pin = OTR_EN_Pin|VLIGHT_EN_Pin|MODBUS_DE_Pin|SDIO_PWR_Pin
                          |LIGHT1_EN_Pin|LIGHT2_EN_Pin;
  GPIO_InitStruct.Mode = GPIO_MODE_OUTPUT_PP;
  GPIO_InitStruct.Pull = GPIO_NOPULL;
  GPIO_InitStruct.Speed = GPIO_SPEED_FREQ_LOW;
  HAL_GPIO_Init(GPIOD, &GPIO_InitStruct);

  /*Configure GPIO pins : DEBUG_Pin ONEWIRE_LED_Pin */
  GPIO_InitStruct.Pin = DEBUG_Pin|ONEWIRE_LED_Pin;
  GPIO_InitStruct.Mode = GPIO_MODE_OUTPUT_PP;
  GPIO_InitStruct.Pull = GPIO_NOPULL;
  GPIO_InitStruct.Speed = GPIO_SPEED_FREQ_LOW;
  HAL_GPIO_Init(GPIOA, &GPIO_InitStruct);

}

void Error_Handler(void)
{
  __disable_irq();
  while (1)
  {
  }
}
